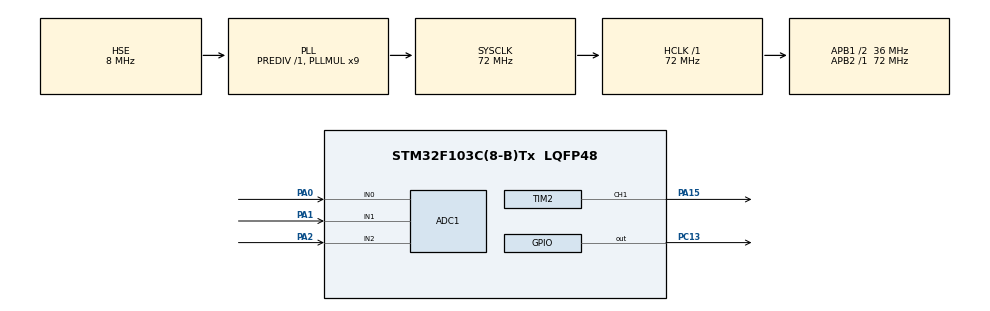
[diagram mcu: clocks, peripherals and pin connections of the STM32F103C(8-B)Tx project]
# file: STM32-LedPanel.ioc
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ADC1.Channel-0\#ChannelRegularConversion=ADC_CHANNEL_0
ADC1.Channel-1\#ChannelRegularConversion=ADC_CHANNEL_1
ADC1.Channel-2\#ChannelRegularConversion=ADC_CHANNEL_2
ADC1.ContinuousConvMode=ENABLE
ADC1.DiscontinuousConvMode=DISABLE
ADC1.NbrOfConversion=3
ADC1.NbrOfConversionFlag=1
ADC1.Rank-0\#ChannelRegularConversion=1
ADC1.Rank-1\#ChannelRegularConversion=2
ADC1.Rank-2\#ChannelRegularConversion=3
ADC1.SamplingTime-0\#ChannelRegularConversion=ADC_SAMPLETIME_71CYCLES_5
ADC1.SamplingTime-1\#ChannelRegularConversion=ADC_SAMPLETIME_71CYCLES_5
ADC1.SamplingTime-2\#ChannelRegularConversion=ADC_SAMPLETIME_71CYCLES_5
ADC1.master=1
Dma.ADC1.0.Direction=DMA_PERIPH_TO_MEMORY
Dma.ADC1.0.Instance=DMA1_Channel1
Dma.ADC1.0.MemDataAlignment=DMA_MDATAALIGN_HALFWORD
Dma.ADC1.0.MemInc=DMA_MINC_ENABLE
Dma.ADC1.0.Mode=DMA_CIRCULAR
Dma.ADC1.0.PeriphDataAlignment=DMA_PDATAALIGN_HALFWORD
Dma.ADC1.0.PeriphInc=DMA_PINC_DISABLE
Dma.ADC1.0.Priority=DMA_PRIORITY_LOW
Dma.Request0=ADC1
Dma.Request1=TIM2_CH1
Dma.TIM2_CH1.1.Direction=DMA_MEMORY_TO_PERIPH
Dma.TIM2_CH1.1.Instance=DMA1_Channel5
Dma.TIM2_CH1.1.MemDataAlignment=DMA_MDATAALIGN_BYTE
Dma.TIM2_CH1.1.MemInc=DMA_MINC_ENABLE
Dma.TIM2_CH1.1.Mode=DMA_CIRCULAR
Dma.TIM2_CH1.1.PeriphDataAlignment=DMA_PDATAALIGN_WORD
Dma.TIM2_CH1.1.PeriphInc=DMA_PINC_DISABLE
Dma.TIM2_CH1.1.Priority=DMA_PRIORITY_HIGH
IWDG.Prescaler=IWDG_PRESCALER_256
Mcu.Family=STM32F1
Mcu.Name=STM32F103C(8-B)Tx
Mcu.Package=LQFP48
NVIC.DMA1_Channel1_IRQn=true\:0\:0\:false\:false\:true\:false\:true
NVIC.DMA1_Channel5_IRQn=true\:0\:0\:false\:false\:true\:false\:true
NVIC.PriorityGroup=NVIC_PRIORITYGROUP_4
NVIC.TIM1_UP_IRQn=true\:0\:0\:false\:false\:true\:true\:true
NVIC.TimeBase=TIM1_UP_IRQn
NVIC.TimeBaseIP=TIM1
PA0-WKUP.Signal=ADCx_IN0
PA1.Signal=ADCx_IN1
PA13.Mode=Serial_Wire
PA13.Signal=SYS_JTMS-SWDIO
PA14.Mode=Serial_Wire
PA14.Signal=SYS_JTCK-SWCLK
PA15.Signal=S_TIM2_CH1_ETR
PA2.Signal=ADCx_IN2
PC13-TAMPER-RTC.PinState=GPIO_PIN_SET
PC13-TAMPER-RTC.Signal=GPIO_Output
PD0-OSC_IN.Mode=HSE-External-Oscillator
PD0-OSC_IN.Signal=RCC_OSC_IN
PD1-OSC_OUT.Mode=HSE-External-Oscillator
PD1-OSC_OUT.Signal=RCC_OSC_OUT
ProjectManager.HeapSize=0x400
ProjectManager.StackSize=0x400
ProjectManager.TargetToolchain=STM32CubeIDE
RCC.ADCPresc=RCC_ADCPCLK2_DIV6
RCC.AHBFreq_Value=72000000
RCC.APB1CLKDivider=RCC_HCLK_DIV2
RCC.APB1Freq_Value=36000000
RCC.APB1TimFreq_Value=72000000
RCC.APB2Freq_Value=72000000
RCC.APB2TimFreq_Value=72000000
RCC.HCLKFreq_Value=72000000
RCC.PLLMUL=RCC_PLL_MUL9
RCC.PLLSourceVirtual=RCC_PLLSOURCE_HSE
RCC.SYSCLKFreq_VALUE=72000000
RCC.SYSCLKSource=RCC_SYSCLKSOURCE_PLLCLK
RCC.USBFreq_Value=48000000
RCC.USBPrescaler=RCC_USBCLKSOURCE_PLL_DIV1_5
SH.ADCx_IN0.0=ADC1_IN0,IN0
SH.ADCx_IN1.0=ADC1_IN1,IN1
SH.ADCx_IN2.0=ADC1_IN2,IN2
SH.S_TIM2_CH1_ETR.0=TIM2_CH1,PWM Generation1 CH1
TIM2.Channel-PWM\ Generation1\ CH1=TIM_CHANNEL_1
TIM2.ClockDivision=TIM_CLOCKDIVISION_DIV1
TIM2.Period=45-1
TIM2.Prescaler=1
VP_IWDG_VS_IWDG.Mode=IWDG_Activate
VP_SYS_VS_tim1.Mode=TIM1
board=custom

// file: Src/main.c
/* USER CODE BEGIN Header */
/**
  ******************************************************************************
  * @file           : main.c
  * @brief          : Main program body
  ******************************************************************************
  * This notice applies to any and all portions of this file
  * that are not between comment pairs USER CODE BEGIN and
  * USER CODE END. Other portions of this file, whether
  * inserted by the user or by software development tools
  * are owned by their respective copyright owners.
  *
  * Copyright (c) 2019 STMicroelectronics International N.V.
  * All rights reserved.
  *
  * Redistribution and use in source and binary forms, with or without
  * modification, are permitted, provided that the following conditions are met:
  *
  * 1. Redistribution of source code must retain the above copyright notice,
  *    this list of conditions and the following disclaimer.
  * 2. Redistributions in binary form must reproduce the above copyright notice,
  *    this list of conditions and the following disclaimer in the documentation
  *    and/or other materials provided with the distribution.
  * 3. Neither the name of STMicroelectronics nor the names of other
  *    contributors to this software may be used to endorse or promote products
  *    derived from this software without specific written permission.
  * 4. This software, including modifications and/or derivative works of this
  *    software, must execute solely and exclusively on microcontroller or
  *    microprocessor devices manufactured by or for STMicroelectronics.
  * 5. Redistribution and use of this software other than as permitted under
  *    this license is void and will automatically terminate your rights under
  *    this license.
  *
  * THIS SOFTWARE IS PROVIDED BY STMICROELECTRONICS AND CONTRIBUTORS "AS IS"
  * AND ANY EXPRESS, IMPLIED OR STATUTORY WARRANTIES, INCLUDING, BUT NOT
  * LIMITED TO, THE IMPLIED WARRANTIES OF MERCHANTABILITY, FITNESS FOR A
  * PARTICULAR PURPOSE AND NON-INFRINGEMENT OF THIRD PARTY INTELLECTUAL PROPERTY
  * RIGHTS ARE DISCLAIMED TO THE FULLEST EXTENT PERMITTED BY LAW. IN NO EVENT
  * SHALL STMICROELECTRONICS OR CONTRIBUTORS BE LIABLE FOR ANY DIRECT, INDIRECT,
  * INCIDENTAL, SPECIAL, EXEMPLARY, OR CONSEQUENTIAL DAMAGES (INCLUDING, BUT NOT
  * LIMITED TO, PROCUREMENT OF SUBSTITUTE GOODS OR SERVICES; LOSS OF USE, DATA,
  * OR PROFITS; OR BUSINESS INTERRUPTION) HOWEVER CAUSED AND ON ANY THEORY OF
  * LIABILITY, WHETHER IN CONTRACT, STRICT LIABILITY, OR TORT (INCLUDING
  * NEGLIGENCE OR OTHERWISE) ARISING IN ANY WAY OUT OF THE USE OF THIS SOFTWARE,
  * EVEN IF ADVISED OF THE POSSIBILITY OF SUCH DAMAGE.
  *
  ******************************************************************************
  */
/* USER CODE END Header */

#include "main.h"

/* USER CODE BEGIN Includes */

#include "setup_hw.h"

/* USER CODE END Includes */

ADC_HandleTypeDef hadc1;
DMA_HandleTypeDef hdma_adc1;

IWDG_HandleTypeDef hiwdg;

TIM_HandleTypeDef htim2;
DMA_HandleTypeDef hdma_tim2_ch1;

void SystemClock_Config(void);
static void MX_GPIO_Init(void);
static void MX_DMA_Init(void);
static void MX_IWDG_Init(void);
static void MX_ADC1_Init(void);
static void MX_TIM2_Init(void);

int main(void)
{

  /* MCU Configuration--------------------------------------------------------*/

  /* Reset of all peripherals, Initializes the Flash interface and the Systick. */
  HAL_Init();

  /* Configure the system clock */
  SystemClock_Config();

  /* Initialize all configured peripherals */
  MX_GPIO_Init();
  MX_DMA_Init();
 // MX_IWDG_Init();
  MX_ADC1_Init();
  MX_TIM2_Init();
  /* USER CODE BEGIN 2 */

  setup_init();

  /* USER CODE END 2 */

  /* Infinite loop */
  while (1)
  {

  }
}

void SystemClock_Config(void)
{
  RCC_OscInitTypeDef RCC_OscInitStruct = {0};
  RCC_ClkInitTypeDef RCC_ClkInitStruct = {0};
  RCC_PeriphCLKInitTypeDef PeriphClkInit = {0};

  /** Initializes the CPU, AHB and APB busses clocks
  */
  RCC_OscInitStruct.OscillatorType = RCC_OSCILLATORTYPE_LSI|RCC_OSCILLATORTYPE_HSE;
  RCC_OscInitStruct.HSEState = RCC_HSE_ON;
  RCC_OscInitStruct.HSEPredivValue = RCC_HSE_PREDIV_DIV1;
  RCC_OscInitStruct.HSIState = RCC_HSI_ON;
  RCC_OscInitStruct.LSIState = RCC_LSI_ON;
  RCC_OscInitStruct.PLL.PLLState = RCC_PLL_ON;
  RCC_OscInitStruct.PLL.PLLSource = RCC_PLLSOURCE_HSE;
  RCC_OscInitStruct.PLL.PLLMUL = RCC_PLL_MUL9;
  if (HAL_RCC_OscConfig(&RCC_OscInitStruct) != HAL_OK)
  {
    Error_Handler();
  }
  /** Initializes the CPU, AHB and APB busses clocks
  */
  RCC_ClkInitStruct.ClockType = RCC_CLOCKTYPE_HCLK|RCC_CLOCKTYPE_SYSCLK
                              |RCC_CLOCKTYPE_PCLK1|RCC_CLOCKTYPE_PCLK2;
  RCC_ClkInitStruct.SYSCLKSource = RCC_SYSCLKSOURCE_PLLCLK;
  RCC_ClkInitStruct.AHBCLKDivider = RCC_SYSCLK_DIV1;
  RCC_ClkInitStruct.APB1CLKDivider = RCC_HCLK_DIV2;
  RCC_ClkInitStruct.APB2CLKDivider = RCC_HCLK_DIV1;

  if (HAL_RCC_ClockConfig(&RCC_ClkInitStruct, FLASH_LATENCY_2) != HAL_OK)
  {
    Error_Handler();
  }
  PeriphClkInit.PeriphClockSelection = RCC_PERIPHCLK_ADC;
  PeriphClkInit.AdcClockSelection = RCC_ADCPCLK2_DIV6;
  if (HAL_RCCEx_PeriphCLKConfig(&PeriphClkInit) != HAL_OK)
  {
    Error_Handler();
  }
}

static void MX_ADC1_Init(void)
{

  ADC_ChannelConfTypeDef sConfig = {0};

  /** Common config
  */
  hadc1.Instance = ADC1;
  hadc1.Init.ScanConvMode = ADC_SCAN_ENABLE;
  hadc1.Init.ContinuousConvMode = ENABLE;
  hadc1.Init.DiscontinuousConvMode = DISABLE;
  hadc1.Init.ExternalTrigConv = ADC_SOFTWARE_START;
  hadc1.Init.DataAlign = ADC_DATAALIGN_RIGHT;
  hadc1.Init.NbrOfConversion = 3;
  if (HAL_ADC_Init(&hadc1) != HAL_OK)
  {
    Error_Handler();
  }
  /** Configure Regular Channel
  */
  sConfig.Channel = ADC_CHANNEL_0;
  sConfig.Rank = ADC_REGULAR_RANK_1;
  sConfig.SamplingTime = ADC_SAMPLETIME_71CYCLES_5;
  if (HAL_ADC_ConfigChannel(&hadc1, &sConfig) != HAL_OK)
  {
    Error_Handler();
  }
  /** Configure Regular Channel
  */
  sConfig.Channel = ADC_CHANNEL_1;
  sConfig.Rank = ADC_REGULAR_RANK_2;
  if (HAL_ADC_ConfigChannel(&hadc1, &sConfig) != HAL_OK)
  {
    Error_Handler();
  }
  /** Configure Regular Channel
  */
  sConfig.Channel = ADC_CHANNEL_2;
  sConfig.Rank = ADC_REGULAR_RANK_3;
  if (HAL_ADC_ConfigChannel(&hadc1, &sConfig) != HAL_OK)
  {
    Error_Handler();
  }

}

static void MX_IWDG_Init(void)
{

  hiwdg.Instance = IWDG;
  hiwdg.Init.Prescaler = IWDG_PRESCALER_256;
  hiwdg.Init.Reload = 4095;
  if (HAL_IWDG_Init(&hiwdg) != HAL_OK)
  {
    Error_Handler();
  }

}

static void MX_TIM2_Init(void)
{

  TIM_MasterConfigTypeDef sMasterConfig = {0};
  TIM_OC_InitTypeDef sConfigOC = {0};

  htim2.Instance = TIM2;
  htim2.Init.Prescaler = 1;
  htim2.Init.CounterMode = TIM_COUNTERMODE_UP;
  htim2.Init.Period = 45-1;
  htim2.Init.ClockDivision = TIM_CLOCKDIVISION_DIV1;
  htim2.Init.AutoReloadPreload = TIM_AUTORELOAD_PRELOAD_DISABLE;
  if (HAL_TIM_PWM_Init(&htim2) != HAL_OK)
  {
    Error_Handler();
  }
  sMasterConfig.MasterOutputTrigger = TIM_TRGO_RESET;
  sMasterConfig.MasterSlaveMode = TIM_MASTERSLAVEMODE_DISABLE;
  if (HAL_TIMEx_MasterConfigSynchronization(&htim2, &sMasterConfig) != HAL_OK)
  {
    Error_Handler();
  }
  sConfigOC.OCMode = TIM_OCMODE_PWM1;
  sConfigOC.Pulse = 0;
  sConfigOC.OCPolarity = TIM_OCPOLARITY_HIGH;
  sConfigOC.OCFastMode = TIM_OCFAST_DISABLE;
  if (HAL_TIM_PWM_ConfigChannel(&htim2, &sConfigOC, TIM_CHANNEL_1) != HAL_OK)
  {
    Error_Handler();
  }
  HAL_TIM_MspPostInit(&htim2);

}

static void MX_DMA_Init(void)
{

  /* DMA controller clock enable */
  __HAL_RCC_DMA1_CLK_ENABLE();

  /* DMA interrupt init */
  /* DMA1_Channel1_IRQn interrupt configuration */
  HAL_NVIC_SetPriority(DMA1_Channel1_IRQn, 0, 0);
  HAL_NVIC_EnableIRQ(DMA1_Channel1_IRQn);
  /* DMA1_Channel5_IRQn interrupt configuration */
  HAL_NVIC_SetPriority(DMA1_Channel5_IRQn, 0, 0);
  HAL_NVIC_EnableIRQ(DMA1_Channel5_IRQn);

}

static void MX_GPIO_Init(void)
{
  GPIO_InitTypeDef GPIO_InitStruct = {0};

  /* GPIO Ports Clock Enable */
  __HAL_RCC_GPIOC_CLK_ENABLE();
  __HAL_RCC_GPIOD_CLK_ENABLE();
  __HAL_RCC_GPIOA_CLK_ENABLE();

  /*Configure GPIO pin Output Level */
  HAL_GPIO_WritePin(GPIOC, GPIO_PIN_13, GPIO_PIN_SET);

  /*Configure GPIO pin : PC13 */
  GPIO_InitStruct.Pin = GPIO_PIN_13;
  GPIO_InitStruct.Mode = GPIO_MODE_OUTPUT_PP;
  GPIO_InitStruct.Pull = GPIO_NOPULL;
  GPIO_InitStruct.Speed = GPIO_SPEED_FREQ_LOW;
  HAL_GPIO_Init(GPIOC, &GPIO_InitStruct);

}

void HAL_TIM_PeriodElapsedCallback(TIM_HandleTypeDef *htim)
{
  if (htim->Instance == TIM1) {
    HAL_IncTick();
  }
}

void Error_Handler(void)
{
}

/************************ (C) COPYRIGHT STMicroelectronics *****END OF FILE****/
